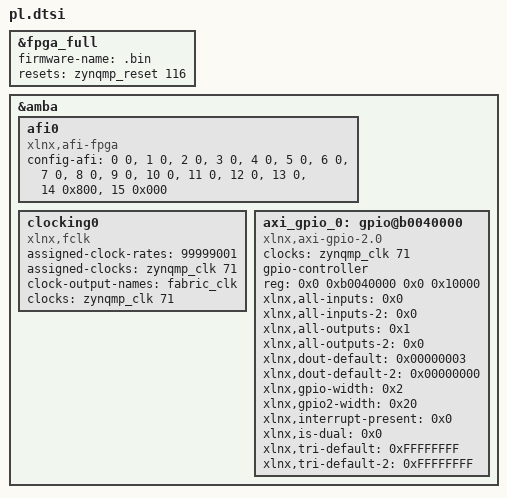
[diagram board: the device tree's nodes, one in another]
/*
 * CAUTION: This file is automatically generated by Xilinx.
 * Version: XSCT 2020.2
 * Today is: Sat Apr 17 21:40:25 2021
 */


/dts-v1/;
/plugin/;
/ {
	fragment@0 {
		target = <&fpga_full>;
		overlay0: __overlay__ {
			#address-cells = <2>;
			#size-cells = <2>;
			firmware-name = ".bin";
			resets = <&zynqmp_reset 116>;
		};
	};
	fragment@1 {
		target = <&amba>;
		overlay1: __overlay__ {
			afi0: afi0 {
				compatible = "xlnx,afi-fpga";
				config-afi = < 0 0>, <1 0>, <2 0>, <3 0>, <4 0>, <5 0>, <6 0>, <7 0>, <8 0>, <9 0>, <10 0>, <11 0>, <12 0>, <13 0>, <14 0x800>, <15 0x000>;
			};
			clocking0: clocking0 {
				#clock-cells = <0>;
				assigned-clock-rates = <99999001>;
				assigned-clocks = <&zynqmp_clk 71>;
				clock-output-names = "fabric_clk";
				clocks = <&zynqmp_clk 71>;
				compatible = "xlnx,fclk";
			};
		};
	};
	fragment@2 {
		target = <&amba>;
		overlay2: __overlay__ {
			#address-cells = <2>;
			#size-cells = <2>;
			axi_gpio_0: gpio@b0040000 {
				#gpio-cells = <3>;
				clock-names = "s_axi_aclk";
				clocks = <&zynqmp_clk 71>;
				compatible = "xlnx,axi-gpio-2.0", "xlnx,xps-gpio-1.00.a";
				gpio-controller ;
				reg = <0x0 0xb0040000 0x0 0x10000>;
				xlnx,all-inputs = <0x0>;
				xlnx,all-inputs-2 = <0x0>;
				xlnx,all-outputs = <0x1>;
				xlnx,all-outputs-2 = <0x0>;
				xlnx,dout-default = <0x00000003>;
				xlnx,dout-default-2 = <0x00000000>;
				xlnx,gpio-width = <0x2>;
				xlnx,gpio2-width = <0x20>;
				xlnx,interrupt-present = <0x0>;
				xlnx,is-dual = <0x0>;
				xlnx,tri-default = <0xFFFFFFFF>;
				xlnx,tri-default-2 = <0xFFFFFFFF>;
			};
		};
	};
};
